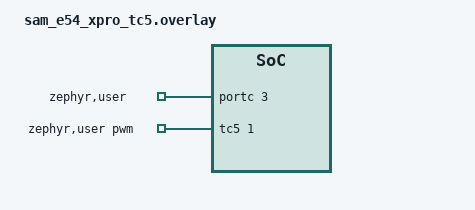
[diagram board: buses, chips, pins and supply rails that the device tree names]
/*
 * Copyright (c) 2025-2026 Microchip Technology Inc.
 * SPDX-License-Identifier: Apache-2.0
 */

/* connect PB15 to PC03 */

#define PWM_NODE     tc5
#define PWM_PINCTRL  tc5_pwm_default
#include "mchp_pwm_loopback_support.dtsi"

/ {
	zephyr,user {
		pwms = <&tc5 1 PWM_MSEC(1) 0>;
		gpios = <&portc 3 GPIO_ACTIVE_HIGH>;
	};
};

&portc {
	status = "okay";
};

&pinctrl {
	tc5_pwm_default: tc5_pwm_default {
		group1 {
			pinmux = <PB15E_TC5_WO1>;
		};
	};
};
